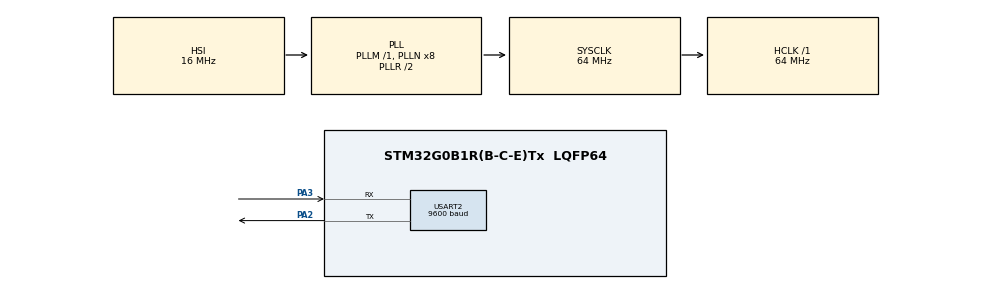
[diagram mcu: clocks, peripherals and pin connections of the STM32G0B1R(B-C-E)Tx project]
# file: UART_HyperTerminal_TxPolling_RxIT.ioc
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Mcu.Family=STM32G0
Mcu.Name=STM32G0B1R(B-C-E)Tx
Mcu.Package=LQFP64
NVIC.USART2_LPUART2_IRQn=true\:0\:0\:false\:false\:true\:true\:true\:true
PA2.GPIO_PuPd=GPIO_PULLUP
PA2.Mode=Asynchronous
PA2.Signal=USART2_TX
PA3.GPIO_PuPd=GPIO_PULLUP
PA3.Mode=Asynchronous
PA3.Signal=USART2_RX
ProjectManager.HeapSize=0x200
ProjectManager.StackSize=0x400
ProjectManager.TargetToolchain=EWARM V8.50
RCC.ADCFreq_Value=64000000
RCC.AHBFreq_Value=64000000
RCC.CortexFreq_Value=64000000
RCC.EXTERNAL_CLOCK_VALUE=48000
RCC.HCLKFreq_Value=64000000
RCC.HSE_VALUE=8000000
RCC.HSI48_VALUE=48000000
RCC.HSI_VALUE=16000000
RCC.LSE_VALUE=32768
RCC.SYSCLKFreq_VALUE=64000000
RCC.SYSCLKSource=RCC_SYSCLKSOURCE_PLLCLK
RCC.USBFreq_Value=48000000
RCC.VCOOutputFreq_Value=128000000
USART2.AutoBaudRateEnableParam=UART_ADVFEATURE_AUTOBAUDRATE_DISABLE
USART2.BaudRate=9600
USART2.ClockPrescaler=PRESCALER_DIV1
USART2.DMADisableonRxErrorParam=ADVFEATURE_DMA_ENABLEONRXERROR
USART2.DataInvertParam=ADVFEATURE_DATAINV_DISABLE
USART2.FIFOMode=FIFOMODE_DISABLE
USART2.MSBFirstParam=ADVFEATURE_MSBFIRST_DISABLE
USART2.Mode=MODE_TX_RX
USART2.OneBitSampling=UART_ONE_BIT_SAMPLE_DISABLE
USART2.OverSampling=UART_OVERSAMPLING_16
USART2.OverrunDisableParam=ADVFEATURE_OVERRUN_ENABLE
USART2.Parity=PARITY_ODD
USART2.RXFIFOThreshold=RXFIFO_THRESHOLD_1EIGHTHFULL
USART2.RxPinLevelInvertParam=ADVFEATURE_RXINV_DISABLE
USART2.StopBits=STOPBITS_1
USART2.SwapParam=ADVFEATURE_SWAP_DISABLE
USART2.TXFIFOThreshold=TXFIFO_THRESHOLD_1EIGHTHFULL
USART2.TxPinLevelInvertParam=ADVFEATURE_TXINV_DISABLE
USART2.VirtualMode-Asynchronous=VM_ASYNC
USART2.WordLength=WORDLENGTH_8B
VP_SYS_VS_DBSignals.Mode=DisableDeadBatterySignals
board=NUCLEO-G0B1RE

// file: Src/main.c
/* USER CODE BEGIN Header */
/**
  ******************************************************************************
  * @file    UART/UART_HyperTerminal_TxPolling_RxIT/Src/main.c
  * @author  MCD Application Team
  * @brief   This sample code shows how to use UART HAL and LL APIs to transmit
  *          data in polling mode while receiving data in Interrupt mode, by mixing
  *          use of LL and HAL APIs;
  *          HAL driver is used to perform UART configuration,
  *          then TX transfer procedure is based on HAL APIs use (polling)
  *               RX transfer procedure is based on LL APIs use (IT)
  ******************************************************************************
  * @attention
  *
  * Copyright (c) 2020 STMicroelectronics.
  * All rights reserved.
  *
  * This software is licensed under terms that can be found in the LICENSE file
  * in the root directory of this software component.
  * If no LICENSE file comes with this software, it is provided AS-IS.
  *
  ******************************************************************************
  */
/* USER CODE END Header */
#include "main.h"
#include <stdio.h>
#include <string.h>

UART_HandleTypeDef huart2;

/* USER CODE BEGIN PV */

/* Buffer used for transmission */

/* Buffer used for reception */
uint8_t aRXBufferA[RX_BUFFER_SIZE];
uint8_t aRXBufferB[RX_BUFFER_SIZE];
__IO uint32_t uwNbReceivedChars = 0;
__IO uint32_t uwBufferReadyIndication = 0;
uint8_t *pBufferReadyForUser;
uint8_t *pBufferReadyForReception;

/* USER CODE END PV */

void SystemClock_Config(void);
static void MX_GPIO_Init(void);
static void MX_USART2_UART_Init(void);

int main(void)
{

  HAL_Init();
  BSP_LED_Init(LED4);
  SystemClock_Config();
  MX_GPIO_Init();
  MX_USART2_UART_Init();

  uint32_t counter = 0;
  char msg[50];
  sprintf(msg, "\n\n\rHello from HAL + C \n\r");
  HAL_UART_Transmit(&huart2, (uint8_t*)msg, strlen(msg), 1000);

#if 0
  // Example 1 - overflow
  uint8_t x = 255;
  x = x + 1;
  sprintf(msg, "example 1 x value %u\n\r", x);
  HAL_UART_Transmit(&huart2, (uint8_t*)msg, strlen(msg), 1000);
#endif

#if 0
  // Example 2 - Unsafe Shared Access
  uint32_t *a = &counter;
  uint32_t *b = &counter;
   sprintf(msg, "example 2 a value %ld b value %ld \n\r", *a,*b);
     HAL_UART_Transmit(&huart2, (uint8_t*)msg, strlen(msg), 1000);
#endif

  while (1)
  {
      sprintf(msg, "alive %ld\r", counter);

      HAL_UART_Transmit(&huart2, (uint8_t*)msg, strlen(msg), 1000);

      BSP_LED_Toggle(LED4);
      HAL_Delay(1000);

      counter++;
  }
}

void SystemClock_Config(void)
{
  RCC_OscInitTypeDef RCC_OscInitStruct = {0};
  RCC_ClkInitTypeDef RCC_ClkInitStruct = {0};

  /** Configure the main internal regulator output voltage
  */
  HAL_PWREx_ControlVoltageScaling(PWR_REGULATOR_VOLTAGE_SCALE1);

  /** Initializes the RCC Oscillators according to the specified parameters
  * in the RCC_OscInitTypeDef structure.
  */
  RCC_OscInitStruct.OscillatorType = RCC_OSCILLATORTYPE_HSI;
  RCC_OscInitStruct.HSIState = RCC_HSI_ON;
  RCC_OscInitStruct.HSIDiv = RCC_HSI_DIV1;
  RCC_OscInitStruct.HSICalibrationValue = RCC_HSICALIBRATION_DEFAULT;
  RCC_OscInitStruct.PLL.PLLState = RCC_PLL_ON;
  RCC_OscInitStruct.PLL.PLLSource = RCC_PLLSOURCE_HSI;
  RCC_OscInitStruct.PLL.PLLM = RCC_PLLM_DIV1;
  RCC_OscInitStruct.PLL.PLLN = 8;
  RCC_OscInitStruct.PLL.PLLP = RCC_PLLP_DIV2;
  RCC_OscInitStruct.PLL.PLLQ = RCC_PLLQ_DIV2;
  RCC_OscInitStruct.PLL.PLLR = RCC_PLLR_DIV2;
  if (HAL_RCC_OscConfig(&RCC_OscInitStruct) != HAL_OK)
  {
    Error_Handler();
  }

  /** Initializes the CPU, AHB and APB buses clocks
  */
  RCC_ClkInitStruct.ClockType = RCC_CLOCKTYPE_HCLK|RCC_CLOCKTYPE_SYSCLK
                              |RCC_CLOCKTYPE_PCLK1;
  RCC_ClkInitStruct.SYSCLKSource = RCC_SYSCLKSOURCE_PLLCLK;
  RCC_ClkInitStruct.AHBCLKDivider = RCC_SYSCLK_DIV1;
  RCC_ClkInitStruct.APB1CLKDivider = RCC_HCLK_DIV1;

  if (HAL_RCC_ClockConfig(&RCC_ClkInitStruct, FLASH_LATENCY_2) != HAL_OK)
  {
    Error_Handler();
  }
}

static void MX_USART2_UART_Init(void)
{

  huart2.Instance = USART2;
  huart2.Init.BaudRate = 115200;
  huart2.Init.WordLength = UART_WORDLENGTH_8B;
  huart2.Init.StopBits = UART_STOPBITS_1;
  huart2.Init.Parity = UART_PARITY_NONE;
  huart2.Init.Mode = UART_MODE_TX_RX;
  huart2.Init.HwFlowCtl = UART_HWCONTROL_NONE;
  huart2.Init.OverSampling = UART_OVERSAMPLING_16;
  huart2.Init.OneBitSampling = UART_ONE_BIT_SAMPLE_DISABLE;
  huart2.Init.ClockPrescaler = UART_PRESCALER_DIV1;
  huart2.AdvancedInit.AdvFeatureInit = UART_ADVFEATURE_NO_INIT;
  if (HAL_UART_Init(&huart2) != HAL_OK)
  {
    Error_Handler();
  }
  if (HAL_UARTEx_SetTxFifoThreshold(&huart2, UART_TXFIFO_THRESHOLD_1_8) != HAL_OK)
  {
    Error_Handler();
  }
  if (HAL_UARTEx_SetRxFifoThreshold(&huart2, UART_RXFIFO_THRESHOLD_1_8) != HAL_OK)
  {
    Error_Handler();
  }
  if (HAL_UARTEx_DisableFifoMode(&huart2) != HAL_OK)
  {
    Error_Handler();
  }

  /* USER CODE BEGIN 2 */

  /*## Configure UART peripheral for reception process (using LL) ##########*/
  /* Initializes Buffer swap mechanism :
     2 physical buffers aRXBufferA and aRXBufferB (RX_BUFFER_SIZE length)
     Any data received will be stored in active buffer : the number max of
     data received is RX_BUFFER_SIZE */
  pBufferReadyForReception = aRXBufferA;
  pBufferReadyForUser      = aRXBufferB;
  uwNbReceivedChars = 0;
  uwBufferReadyIndication = 0;

  LL_USART_EnableIT_RXNE(USART2);
  LL_USART_EnableIT_ERROR(USART2);

}

static void MX_GPIO_Init(void)
{

  /* GPIO Ports Clock Enable */
  __HAL_RCC_GPIOA_CLK_ENABLE();

}

/* USER CODE BEGIN 4 */

/**
  * @brief  Rx Transfer completed callback
  * @note   This example shows a simple way to report end of IT Rx transfer, and
  *         you can add your own implementation.
  * @retval None
  */
void UART_CharReception_Callback(void)
{
uint8_t *ptemp;

  /* Read Received character. RXNE flag is cleared by reading of RDR register */
  pBufferReadyForReception[uwNbReceivedChars++] = LL_USART_ReceiveData8(USART2);

  /* Checks if Buffer full indication has to be set */
  if (uwNbReceivedChars >= RX_BUFFER_SIZE)
  {
    /* Set Buffer swap indication */
    uwBufferReadyIndication = 1;

    /* Swap buffers for next bytes to be received */
    ptemp = pBufferReadyForUser;
    pBufferReadyForUser = pBufferReadyForReception;
    pBufferReadyForReception = ptemp;
    uwNbReceivedChars = 0;
  }
}

/**
  * @brief  UART error callbacks
  * @note   This example shows a simple way to report transfer error, and you can
  *         add your own implementation.
  * @retval None
  */
void UART_Error_Callback(void)
{
  __IO uint32_t isr_reg;

  /* Disable USARTx_IRQn */
  NVIC_DisableIRQ(USART2_LPUART2_IRQn);

  /* Error handling example :
    - Read USART ISR register to identify flag that leads to IT raising
    - Perform corresponding error handling treatment according to flag
  */
  isr_reg = LL_USART_ReadReg(USART2, ISR);
  if (isr_reg & LL_USART_ISR_NE)
  {
    /* Turn LED4 on: Transfer error in reception/transmission process */
    BSP_LED_On(LED4);
  }
  else
  {
    /* Turn LED4 on: Transfer error in reception/transmission process */
    BSP_LED_On(LED4);
  }
}

/* USER CODE END 4 */

void Error_Handler(void)
{
  /* USER CODE BEGIN Error_Handler_Debug */
  /* User can add his own implementation to report the HAL error return state */
  /* Turn LED4 to on for error */
  BSP_LED_On(LED4);
  while(1)
  {
  }
  /* USER CODE END Error_Handler_Debug */
}
